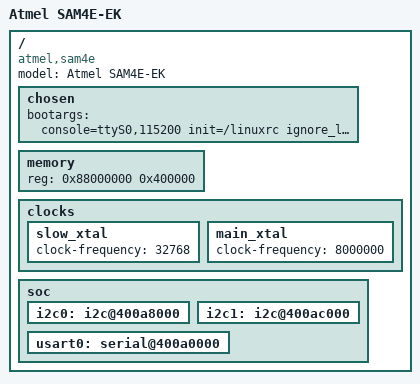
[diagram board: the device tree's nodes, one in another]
/*
 * sama5d3.dtsi - Device Tree Include file for SAM4E
 *
 *  Copyright (C) 2013 Atmel,(setup borrowed from sama5d3.dtsi)
 *		  2014 Marek Roszko
 *
 * Licensed under GPLv2 or later.
 */

/dts-v1/;
#include "sam4e.dtsi"

/ {
	model = "Atmel SAM4E-EK";
	compatible = "atmel,sam4e";

	chosen {
		bootargs = "console=ttyS0,115200 init=/linuxrc ignore_loglevel ihash_entries=64 dhash_entries=64 earlyprintk uclinux.physaddr=0x8c400000 root=/dev/mtdblock0";
	};

	memory {
		reg = <0x88000000 0x400000>;
	};

	clocks {
		slow_xtal {
			clock-frequency = <32768>;
		};

		main_xtal {
			clock-frequency = <8000000>;
		};
	};

	soc {

		i2c0: i2c@400a8000 {
			status = "ok";
		};

		i2c1: i2c@400ac000 {
			status = "ok";
		};

		usart0: serial@400a0000 {
			status = "ok";
		};
	};
};
